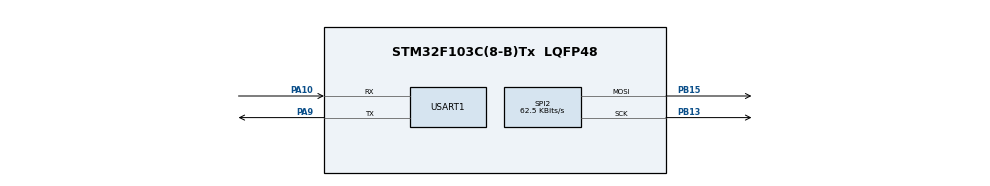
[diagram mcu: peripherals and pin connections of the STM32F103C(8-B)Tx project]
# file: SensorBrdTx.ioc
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Mcu.Family=STM32F1
Mcu.Name=STM32F103C(8-B)Tx
Mcu.Package=LQFP48
NVIC.PriorityGroup=NVIC_PRIORITYGROUP_4
PA10.Mode=Asynchronous
PA10.Signal=USART1_RX
PA9.Mode=Asynchronous
PA9.Signal=USART1_TX
PB13.Mode=TX_Only_Simplex_Unidirect_Master
PB13.Signal=SPI2_SCK
PB15.Mode=TX_Only_Simplex_Unidirect_Master
PB15.Signal=SPI2_MOSI
ProjectManager.HeapSize=0x200
ProjectManager.StackSize=0x400
ProjectManager.TargetToolchain=STM32CubeIDE
RCC.APB1Freq_Value=8000000
RCC.APB2Freq_Value=8000000
SPI2.BaudRatePrescaler=SPI_BAUDRATEPRESCALER_128
SPI2.CalculateBaudRate=62.5 KBits/s
SPI2.Direction=SPI_DIRECTION_2LINES
SPI2.Mode=SPI_MODE_MASTER
SPI2.VirtualType=VM_MASTER
USART1.VirtualMode=VM_ASYNC
board=custom

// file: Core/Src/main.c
/* USER CODE BEGIN Header */
/**
  ******************************************************************************
  * @file           : main.c
  * @brief          : Main program body
  ******************************************************************************
  * @attention
  *
  * Copyright (c) 2023 STMicroelectronics.
  * All rights reserved.
  *
  * This software is licensed under terms that can be found in the LICENSE file
  * in the root directory of this software component.
  * If no LICENSE file comes with this software, it is provided AS-IS.
  *
  ******************************************************************************
  */
/* USER CODE END Header */
#include "main.h"

/* USER CODE BEGIN Includes */
#include <stdio.h>
/* USER CODE END Includes */

SPI_HandleTypeDef hspi2;

UART_HandleTypeDef huart1;

void	SystemClock_Config(void);
static void	MX_GPIO_Init(void);
static void	MX_SPI2_Init(void);
static void	MX_USART1_UART_Init(void);
/* USER CODE BEGIN PFP */
int	_write(int file, char *data, int len)
{
	// arbitrary timeout 1000
	HAL_StatusTypeDef status =
		HAL_UART_Transmit(&huart1, (uint8_t *)data, len, 1000);

	// return # of bytes written - as best we can tell
	return (status == HAL_OK ? len : 0);
}

/* USER CODE END PFP */

int	main(void)
{

	/* MCU Configuration--------------------------------------------------------*/

	/* Reset of all peripherals,
		Initializes the Flash interface and the Systick. */
	HAL_Init();

	/* Configure the system clock */
	SystemClock_Config();

	/* Initialize all configured peripherals */
	MX_GPIO_Init();
	MX_SPI2_Init();
	MX_USART1_UART_Init();
	/* USER CODE BEGIN 2 */
	uint8_t sensorDataTransfer[2] = {0xAA, 0xBB};
	uint8_t dummyData = 0x01;
	/* USER CODE END 2 */

	/* Infinite loop */
	while (1)
	{

		/* USER CODE BEGIN 3 */
		HAL_Delay(1000);
		HAL_SPI_Transmit(&hspi2, sensorDataTransfer, 2, HAL_MAX_DELAY);
		HAL_Delay(10);
		// HAL_SPI_Receive(&hspi2, &sensorDataRecieve, 1, 5000);
	}
	/* USER CODE END 3 */
}

void	SystemClock_Config(void)
{
	RCC_OscInitTypeDef RCC_OscInitStruct = {0};
	RCC_ClkInitTypeDef RCC_ClkInitStruct = {0};

	/** Initializes the RCC Oscillators according to the specified parameters
  * in the RCC_OscInitTypeDef structure.
  */
	RCC_OscInitStruct.OscillatorType = RCC_OSCILLATORTYPE_HSI;
	RCC_OscInitStruct.HSIState = RCC_HSI_ON;
	RCC_OscInitStruct.HSICalibrationValue = RCC_HSICALIBRATION_DEFAULT;
	RCC_OscInitStruct.PLL.PLLState = RCC_PLL_NONE;
	if (HAL_RCC_OscConfig(&RCC_OscInitStruct) != HAL_OK)
	{
		Error_Handler();
	}

	/** Initializes the CPU, AHB and APB buses clocks
  */
	RCC_ClkInitStruct.ClockType = RCC_CLOCKTYPE_HCLK | RCC_CLOCKTYPE_SYSCLK | RCC_CLOCKTYPE_PCLK1 | RCC_CLOCKTYPE_PCLK2;
	RCC_ClkInitStruct.SYSCLKSource = RCC_SYSCLKSOURCE_HSI;
	RCC_ClkInitStruct.AHBCLKDivider = RCC_SYSCLK_DIV1;
	RCC_ClkInitStruct.APB1CLKDivider = RCC_HCLK_DIV1;
	RCC_ClkInitStruct.APB2CLKDivider = RCC_HCLK_DIV1;

	if (HAL_RCC_ClockConfig(&RCC_ClkInitStruct, FLASH_LATENCY_0) != HAL_OK)
	{
		Error_Handler();
	}
}

static void	MX_SPI2_Init(void)
{

	/* SPI2 parameter configuration*/
	hspi2.Instance = SPI2;
	hspi2.Init.Mode = SPI_MODE_MASTER;
	hspi2.Init.Direction = SPI_DIRECTION_2LINES;
	hspi2.Init.DataSize = SPI_DATASIZE_8BIT;
	hspi2.Init.CLKPolarity = SPI_POLARITY_LOW;
	hspi2.Init.CLKPhase = SPI_PHASE_1EDGE;
	hspi2.Init.NSS = SPI_NSS_SOFT;
	hspi2.Init.BaudRatePrescaler = SPI_BAUDRATEPRESCALER_128;
	hspi2.Init.FirstBit = SPI_FIRSTBIT_MSB;
	hspi2.Init.TIMode = SPI_TIMODE_DISABLE;
	hspi2.Init.CRCCalculation = SPI_CRCCALCULATION_DISABLE;
	hspi2.Init.CRCPolynomial = 10;
	if (HAL_SPI_Init(&hspi2) != HAL_OK)
	{
		Error_Handler();
	}
}

static void	MX_USART1_UART_Init(void)
{

	huart1.Instance = USART1;
	huart1.Init.BaudRate = 115200;
	huart1.Init.WordLength = UART_WORDLENGTH_8B;
	huart1.Init.StopBits = UART_STOPBITS_1;
	huart1.Init.Parity = UART_PARITY_NONE;
	huart1.Init.Mode = UART_MODE_TX_RX;
	huart1.Init.HwFlowCtl = UART_HWCONTROL_NONE;
	huart1.Init.OverSampling = UART_OVERSAMPLING_16;
	if (HAL_UART_Init(&huart1) != HAL_OK)
	{
		Error_Handler();
	}
}

static void	MX_GPIO_Init(void)
{
	/* GPIO Ports Clock Enable */
	__HAL_RCC_GPIOB_CLK_ENABLE();
	__HAL_RCC_GPIOA_CLK_ENABLE();
}

void	Error_Handler(void)
{
	__disable_irq();
	while (1)
	{
	}
}

#ifdef USE_FULL_ASSERT
/**
  * @brief  Reports the name of the source file and the source line number
  *         where the assert_param error has occurred.
  * @param  file: pointer to the source file name
  * @param  line: assert_param error line source number
  * @retval None
  */
void	assert_failed(uint8_t *file, uint32_t line)
{
	/* USER CODE BEGIN 6 */
	/* User can add his own implementation to report the file name and line number,
     ex: printf("Wrong parameters value: file %s on line %d\r\n", file,
		line) */
	/* USER CODE END 6 */
}
#endif /* USE_FULL_ASSERT */
